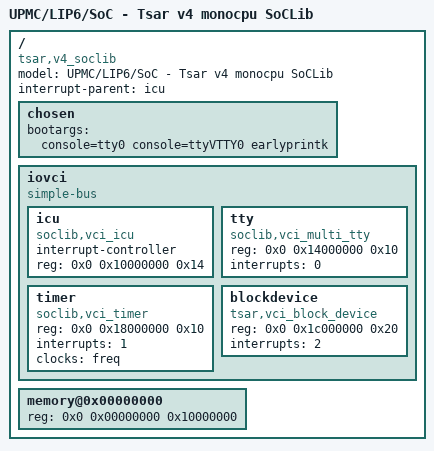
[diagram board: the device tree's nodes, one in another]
/*
 * DTS file for TSARV4 monocpu on SoCLib
 */

/dts-v1/;

/include/ "skeleton.dtsi"
/include/ "cpu_mono.dtsi"
/include/ "freq_soclib.dtsi"

/ {
	model = "UPMC/LIP6/SoC - Tsar v4 monocpu SoCLib";
	compatible = "tsar,v4_soclib", "tsar,monocpu_v4_soclib";
	interrupt-parent = <&icu>;

	chosen {
		/* the day we have a uart8250 compatible component, we can use
		 * the earlycon param to get earlyprintk */
		/* bootargs = "earlycon=uart8250,mmio,0x00000000"; */

		/* this is for maximum debug */
		/* bootargs = "ignore_loglevel initcall_debug"; */

		/* display console in both framebuffer and tty (the last one
		 * becomes the default one) */
		bootargs = "console=tty0 console=ttyVTTY0 earlyprintk";
	};

	iovci {
		compatible = "simple-bus";
		#address-cells = <2>;
		#size-cells = <1>;
		ranges; // identity mapping between root addressing and vci network

		icu: icu {
			/* the vci_icu is a N->1 interrupt controller */
			compatible = "soclib,vci_icu";
			interrupt-controller;
			#interrupt-cells = <1>;
			reg = <0x0 0x10000000 0x14>;
		};

		tty: tty {
			compatible = "soclib,vci_multi_tty";
			reg = <0x0 0x14000000 0x10>;
			interrupts = <0>;
		};

		timer {
			compatible = "soclib,vci_timer";
			reg = <0x0 0x18000000 0x10>;
			interrupts = <1>;
			clocks = <&freq>;
		};

		blockdevice {
			compatible = "tsar,vci_block_device";
			reg = <0x0 0x1c000000 0x20>;
			interrupts = <2>;
		};

		/*
		framebuffer {
			compatible = "tsar,vci_framebuffer", "simple-framebuffer";
			reg = <0x0 0x20000000 (640 * 680 * 2)>;
			width = <640>;
			height = <480>;
			stride = <(640 * 2)>;
			format = "r5g6b5";
		};
		*/
	};

	memory@0x00000000 {
		device_type = "memory";
		reg = <0x0 0x00000000 0x10000000>;
	};
};
